# psc3m6 register map
Vendor: Infineon Technologies; Series: PSC3M6; File version: 1.0
CPU: CM33 r0p1, little endian, MPU, FPU, DSP, VTOR, 3 interrupt priority bits, 167 interrupts
Registers are 32-bit, read-write, reset 0x0 unless marked. A register's access mark holds for its fields unless they carry their own. Offsets are from the block's base; [hi:lo] are bit positions; lines under a group give offsets from that group; {n}, {i} and the like mark numbered series.

## DW0 — DW-0/1
Base 0x42180000
Same registers: DW1 0x42190000
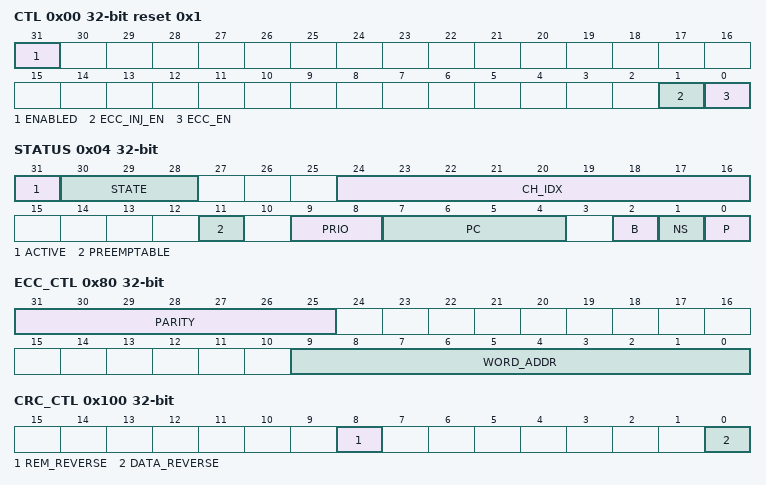
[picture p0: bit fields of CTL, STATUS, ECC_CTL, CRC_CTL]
0x00 CTL reset 0x1 — Control
  [31] ENABLED — IP enable: '0': Disabled. Disabling the IP activates the IP's Active logic reset: Active logic and non-retention MMIO registers are reset (retention MMIO registers are not affected). Note that DW SRAM writes/reads are possible when ENABLED=0 also. '1': Enabled.
  [1] ECC_INJ_EN — Enable parity injection for SRAM. When '1', the parity (ECC_CTL.PARITY) is used when a full 32-bit write is done to the ECC_CTL.WORD_ADDR word address of the SRAM.
  [0] ECC_EN — Enable SECDED ECC checking (Single Error Correction Double Error Detection Error Correcting Code Functionality). '0': Disabled '1': Enabled
0x04 STATUS ro (reset mask 0xF0000000)
  [31] ACTIVE — Active channel present: '0': No. '1': Yes.
  [30:28] STATE — State of the DW controller. '0': Default/inactive state. '1': Loading descriptor. '2': Loading data element from source location. '3': Storing data element to destination location. '4': CRC functionality (only used for CRC transfer descriptor type). '5': Update of active control information (e.g. source and destination addresses) and wait for trigger de-activation. '6': Error.
  [24:16] CH_IDX — Active channel index.
  [11] PREEMPTABLE — Active channel preemptable.
  [9:8] PRIO — Active channel priority.
  [7:4] PC — Active channel protection context.
  [2] B — Active channel, non-bufferable/bufferable access control: '0': non-bufferable '1': bufferable.
  [1] NS — Active channel, secure/non-secure access control: '0': secure. '1': non-secure.
  [0] P — Active channel, user/privileged access control: '0': user mode. '1': privileged mode.
0x20 ACT_DESCR_CTL ro reset not defined — Active descriptor control
  [31:0] DATA
0x24 ACT_DESCR_SRC ro reset not defined — Active descriptor source
  [31:0] DATA — Copy of DESCR_SRC of the currently active descriptor. Base address of source location.
0x28 ACT_DESCR_DST ro reset not defined — Active descriptor destination
  [31:0] DATA — Copy of DESCR_DST of the currently active descriptor. Base address of destination location. Note: For a CRC transfer descriptor, this field should be programmed with the address of the CRC_LFSR_CTL register. The calculated CRC LFSR state is written to this address (through the CRYPTO AHB-Lite master interface) when the input trigger is processed. The write transfer will be submitted to the CPUSS and PERI protection schemes.
0x30 ACT_DESCR_X_CTL ro reset not defined — Active descriptor X loop control
  [31:0] DATA — Copy of DESCR_X_CTL of the currently active descriptor. [11:0] SRC_X_INCR Specifies increment of source address for each X loop iteration (in multiples of SRC_TRANSFER_SIZE). This field is a signed number in the range [-2048, 2047]. If this field is '0', the source address is not incremented. This is useful for reading from RX FIFO structures. [23:12] DST_X_INCR Specifies increment of destination address for each X loop iteration (in multiples of DST_TRANSFER_SIZE). This field is a signed number in the range [-2048, 2047]. If this field is '0', the destination address is not incremented. This is useful for writing to TX FIFO structures. Note: this field is not used for CRC transfer descriptors and must be set to '0'. [31:24] X_COUNT Number of iterations (minus 1) of the 'X loop' (X_COUNT+1 is the number of single transfers in a 1D transfer). This field is an unsigned number in the range [0, 255], representing 1 through 256 iterations. For a single transfer descriptor type, descriptor will not have X_CTL.
0x34 ACT_DESCR_Y_CTL ro reset not defined — Active descriptor Y loop control
  [31:0] DATA — Copy of DESCR_Y_CTL of the currently active descriptor. [11:0] SRC_Y_INCR Specifies increment of source address for each Y loop iteration (in multiples of SRC_TRANSFER_SIZE). This field is a signed number in the range [-2048, 2047]. [23:12] DST_Y_INCR Specifies increment of destination address for each Y loop iteration (in multiples of DST_TRANSFER_SIZE). This field is a signed number in the range [-2048, 2047]. [31:24] Y_COUNT Number of iterations (minus 1) of the 'Y loop' (X_COUNT+1)*(Y_COUNT+1) is the number of single transfers in a 2D transfer). This field is an unsigned number in the range [0, 255], representing 1 through 256 iterations. For single, 1D and CRC transfer descriptor types, descriptor will not have Y_CTL.
0x38 ACT_DESCR_NEXT_PTR ro reset not defined — Active descriptor next pointer
  [31:2] ADDR — Copy of DESCR_NEXT_PTR of the currently active descriptor. [31:2] ADDR Address of next descriptor in descriptor list. When this field is '0', this is the last descriptor in the descriptor list.
0x40 ACT_SRC ro reset not defined — Active source
  [31:0] SRC_ADDR — Current address of source location.
0x44 ACT_DST ro reset not defined — Active destination
  [31:0] DST_ADDR — Current address of destination location.
0x80 ECC_CTL — ECC control
  [31:25] PARITY — ECC parity to use for ECC error injection at address WORD_ADDR.
  [9:0] WORD_ADDR — Specifies the word address where an error will be injected. - On a write transfer to this SRAM word address and when CTL.ECC_INJ_EN bit is '1', the parity (PARITY) is injected.
0x100 CRC_CTL — CRC control
  [8] REM_REVERSE — Specifies whether the remainder is bit reversed (reversal is performed after XORing): '0': No. '1': Yes.
  [0] DATA_REVERSE — Specifies the bit order in which a data Byte is processed (reversal is performed after XORing): '0': Most significant bit (bit 1) first. '1': Least significant bit (bit 0) first.
0x110 CRC_DATA_CTL — CRC data control
  [7:0] DATA_XOR — Specifies a byte mask with which each data byte is XOR'd. The XOR is performed before data reversal.
0x120 CRC_POL_CTL — CRC polynomial control
  [31:0] POLYNOMIAL — CRC polynomial. The polynomial is represented WITHOUT the high order bit (this bit is always assumed '1'). The polynomial should be aligned/shifted such that the more significant bits (bit 31 and down) contain the polynomial and the less significant bits (bit 0 and up) contain padding '0's. Some frequently used polynomials: - CRC32: POLYNOMIAL is 0x04c11db7 (x^32 + x^26 + x^23 + x^22 + x^16 + x^12 + x^11 + x^10 + x^8 + x^7 + x^5 + x^4 + x^2 + x + 1). - CRC16: POLYNOMIAL is 0x80050000 (x^16 + x^15 + x^2 + 1, shifted by 16 bit positions). - CRC16 CCITT: POLYNOMIAL is 0x10210000 (x^16 + x^12 + x^5 + 1, shifted by 16 bit positions).
0x130 CRC_LFSR_CTL — CRC LFSR control
  [31:0] LFSR32 — State of a 32-bit Linear Feedback Shift Registers (LFSR) that is used to implement CRC. This register needs to be initialized by SW to provide the CRC seed value. The seed value should be aligned such that the more significant bits (bit 31 and down) contain the seed value and the less significant bits (bit 0 and up) contain padding '0's. Note that SW can write this field. This functionality can be used prevent information leakage (through either CRC_LFSR_CTL or CRC_REM_RESULT).
0x140 CRC_REM_CTL — CRC remainder control
  [31:0] REM_XOR — Specifies a mask with which the CRC_LFSR_CTL.LFSR32 register is XOR'd to produce a remainder. The XOR is performed before remainder reversal.
0x148 CRC_REM_RESULT ro — CRC remainder result
  [31:0] REM — Remainder value. The alignment of the remainder depends on CRC_REM_CTL0.REM_REVERSE: '0': the more significant bits (bit 31 and down) contain the remainder. '1': the less significant bits (bit 0 and up) contain the remainder. Note: This field is combinatorially derived from CRC_LFSR_CTL.LFSR32, CRC_CTL.REM_REVERSE and CRC_REM_CTL.REM_XOR.
{0x8000+0x40*i} CH_STRUCT[{i}] (i=0..15) group — DW channel structure
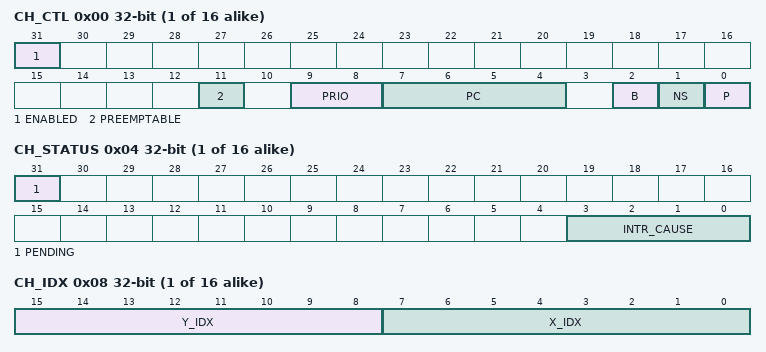
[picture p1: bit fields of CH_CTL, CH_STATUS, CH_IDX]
  0x00 CH_CTL (reset mask 0x80000300) — Channel control
    [31] ENABLED — Channel enable: '0': Disabled. The channel's trigger is ignored and the channel cannot be made pending and therefore cannot be made active. If a pending channel is disabled, the channel is made non pending. If the activate channel is disabled, the channel is de-activated (bus transactions are completed). '1': Enabled. SW sets this field to '1' to enable a specific channel. HW sets this field to '0' on an error interrupt cause (the specific error is specified by CH_STATUS.INTR_CAUSE).
    [11] PREEMPTABLE — Specifies if the channel is preemptable. '0': Not preemptable. '1': Preemptable. This field allows higher priority pending channels (from a higher priority group; i.e. an active channel can NOT be preempted by a pending channel in the same priority group) to preempt the active channel in between 'single transfers' (a 1D transfer consists out of X_COUNT single transfers; a 2D transfer consists out of X_COUNT*Y_COUNT single transfers). Preemption will NOT affect the pending status of channel. As a result, after completion of a higher priority activated channel, the current channel may be reactivated.
    [9:8] PRIO — Channel priority: '0': highest priority. '1' '2' '3': lowest priority. Channels with the same priority constitute a priority group. Priority decoding determines the highest priority pending channel. This channel is determined as follows. First, the highest priority group with pending channels is identified. Second, within this priority group, round robin arbitration is applied. Round robin arbitration (within a priority group) gives the highest priority to the lower channel indices (within the priority group).
    [7:4] PC — Protection context. This field is set with the protection context of the transaction that writes this register; i.e. the 'write data' is ignored and instead the context is inherited from the write transaction (note the field attributes should be HW:RW, SW:R). All transactions for this channel uses the PC field for the protection context. Note: protection context (PC) is routed on 'hauser' bus of the AHB5 bus.
    [2] B — Non-bufferable/bufferable access control: '0': non-bufferable. '1': bufferable. This field is used to indicate to an AMBA bridge that a write transaction can complete without waiting for the destination to accept the write transaction data. All transactions for this channel uses the B field for the non-bufferable/bufferable access control ('hprot[2]').
    [1] NS — Secure/on-secure access control: '0': secure. '1': non-secure. This field is set with the secure/non-secure access control of the transaction that writes this register; i.e. the 'write data' is ignored and instead the access control is inherited from the write transaction (note the field attributes should be HW:RW, SW:R). All transactions for this channel use the NS field for the secure/non-secure access control ('hnonsec').
    [0] P — User/privileged access control: '0': user mode. '1': privileged mode. This field is set with the user/privileged access control of the transaction that writes this register; i.e. the 'write data' is ignored and instead the access control is inherited from the write transaction (note the field attributes should be HW:RW, SW:R). All transactions for this channel use the P field for the user/privileged access control ('hprot[1]').
  0x04 CH_STATUS ro (reset mask 0x80000000) — Channel status
    [31] PENDING — Specifies pending DW channels; i.e. enabled channels whose trigger got activated. This field includes all channels that are in the pending state (not scheduled) or active state (scheduled and performing data transfer(s)).
    [3:0] INTR_CAUSE — Specifies the source of the interrupt cause: '0': NO_INTR '1': COMPLETION '2': SRC_BUS_ERROR '3': DST_BUS_ERROR '4': SRC_MISAL '5': DST_MISAL '6': CURR_PTR_NULL '7': ACTIVE_CH_DISABLED '8': DESCR_BUS_ERROR '9'-'15': Not used. For error related interrupt causes (INTR_CAUSE is '2', '3', ..., '8'), the channel is disabled (HW sets CH_CTL.ENABLED to '0').
  0x08 CH_IDX reset not defined — Channel current indices
    [15:8] Y_IDX — Specifies the Y loop index, with X_COUNT taken from the current descriptor. Note: HW sets this field to '0' when it updates the current descriptor pointer CH_CURR_PTR with DESCR_NEXT_PTR after execution of the current descriptor. Note: SW should set this field to '0' when it updates CH_CURR_PTR.
    [7:0] X_IDX — Specifies the X loop index. In the range of [0, X_COUNT], with X_COUNT taken from the current descriptor. Note: HW sets this field to '0' when it updates the current descriptor pointer CH_CURR_PTR with DESCR_NEXT_PTR after execution of the current descriptor. Note: SW should set this field to '0' when it updates CH_CURR_PTR.
  0x0C CH_CURR_PTR reset not defined — Channel current descriptor pointer
    [31:2] ADDR — Address of current descriptor. When this field is '0', there is no valid descriptor. Note: HW updates the current descriptor pointer CH_CURR_PTR with DESCR_NEXT_PTR after execution of the current descriptor. Note: Typically, when SW updates the current descriptor pointer CH_CURR_PTR, it also sets CH_IDX.X_IDX and CH_IDX.Y_IDX to '0'.
  0x10 INTR — Interrupt
    [0] CH write-1-clears — Set to '1', when event (as specified by CH_STATUS.INTR_CAUSE) is detected. Write INTR.CH field with '1', to clear bit. Write INTR_SET.CH field with '1', to set bit.
  0x14 INTR_SET — Interrupt set
    [0] CH write-1-sets — Write INTR_SET field with '1' to set corresponding INTR.CH field (a write of '0' has no effect).
  0x18 INTR_MASK — Interrupt mask
    [0] CH — Mask for corresponding field in INTR register.
  0x1C INTR_MASKED ro — Interrupt masked
    [0] CH — Logical and of corresponding INTR and INTR_MASK fields.
  0x20 SRAM_DATA0 reset not defined
    [31:0] DATA
  0x24 SRAM_DATA1 reset not defined
    [31:0] DATA — Refer SRAM_DATA0
  0x28 TR_CMD — Channel software trigger
    [0] ACTIVATE write-1-sets — Software trigger. When written with '1', a trigger is generated which sets 'trigger pending' (only if the channel is enabled). A read always returns a 0.
